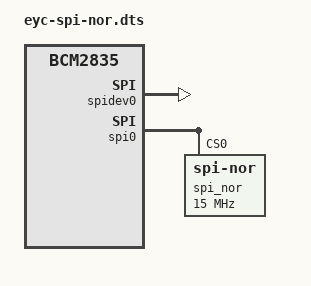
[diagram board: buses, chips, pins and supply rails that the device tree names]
/dts-v1/;
/plugin/;	/* allow undefined references */

/ {
    compatible = "brcm,bcm2835";

    fragment@0 {
        target = <&spidev0>;

        __overlay__ {
            status = "okay";
        };
    };

    fragment@1 {
        target = <&spi0>;

        __overlay__ {
            status = "okay";
            #address-cells = < 0x01 >;
            #size-cells = < 0x00 >;

            spi_nor@0 {
                compatible = "jedec,spi-nor";
                reg = < 0x00 >;
                spi-max-frequency = < 15000000 >;

                //partitions {
                //    compatible = "fixed-partitions";
                //    #address-cells = <1>;
                //    #size-cells = <1>;

                //    partition@80000 {
                //        label = "user";
                //        reg = <0x400000 0x400000>;
                //    };
                //    partition@0 {
                //        label = "conf";
                //        reg = <0x000000 0x400000>;
                //    };
                //};
            };
        };
    };

};

